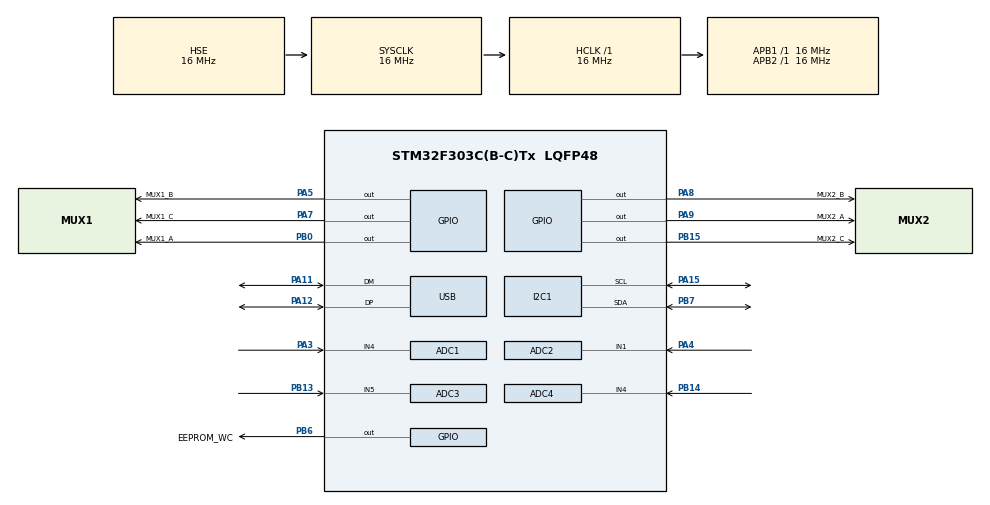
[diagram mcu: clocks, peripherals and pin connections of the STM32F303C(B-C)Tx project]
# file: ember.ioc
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ADC1.Channel-2\#ChannelRegularConversion=ADC_CHANNEL_4
ADC1.ClockPrescaler=ADC_CLOCK_SYNC_PCLK_DIV1
ADC1.Mode=ADC_DUALMODE_REGSIMULT
ADC1.NbrOfConversionFlag=1
ADC1.Offset-2\#ChannelRegularConversion=0
ADC1.OffsetNumber-2\#ChannelRegularConversion=ADC_OFFSET_NONE
ADC1.Rank-2\#ChannelRegularConversion=1
ADC1.SamplingTime-2\#ChannelRegularConversion=ADC_SAMPLETIME_7CYCLES_5
ADC1.SamplingTimeOPAMP-2\#ChannelRegularConversion=ADC_SAMPLETIME_19CYCLES_5
ADC1.TwoSamplingDelay=ADC_TWOSAMPLINGDELAY_1CYCLE
ADC1.master=1
ADC2.Channel-0\#ChannelRegularConversion=ADC_CHANNEL_1
ADC2.ClockPrescaler=ADC_CLOCK_SYNC_PCLK_DIV1
ADC2.Mode=ADC_DUALMODE_REGSIMULT
ADC2.NbrOfConversionFlag=1
ADC2.Offset-0\#ChannelRegularConversion=0
ADC2.OffsetNumber-0\#ChannelRegularConversion=ADC_OFFSET_NONE
ADC2.Rank-0\#ChannelRegularConversion=1
ADC2.SamplingTime-0\#ChannelRegularConversion=ADC_SAMPLETIME_7CYCLES_5
ADC2.SamplingTimeOPAMP-0\#ChannelRegularConversion=ADC_SAMPLETIME_4CYCLES_5
ADC3.Channel-0\#ChannelRegularConversion=ADC_CHANNEL_5
ADC3.ClockPrescaler=ADC_CLOCK_SYNC_PCLK_DIV1
ADC3.Mode=ADC_DUALMODE_REGSIMULT
ADC3.NbrOfConversionFlag=1
ADC3.Offset-0\#ChannelRegularConversion=0
ADC3.OffsetNumber-0\#ChannelRegularConversion=ADC_OFFSET_NONE
ADC3.Rank-0\#ChannelRegularConversion=1
ADC3.SamplingTime-0\#ChannelRegularConversion=ADC_SAMPLETIME_7CYCLES_5
ADC3.master=1
ADC4.Channel-1\#ChannelRegularConversion=ADC_CHANNEL_4
ADC4.ClockPrescaler=ADC_CLOCK_SYNC_PCLK_DIV1
ADC4.Mode=ADC_DUALMODE_REGSIMULT
ADC4.NbrOfConversionFlag=1
ADC4.Offset-1\#ChannelRegularConversion=0
ADC4.OffsetNumber-1\#ChannelRegularConversion=ADC_OFFSET_NONE
ADC4.Rank-1\#ChannelRegularConversion=1
ADC4.SamplingTime-1\#ChannelRegularConversion=ADC_SAMPLETIME_7CYCLES_5
ADC4.SamplingTimeOPAMP-1\#ChannelRegularConversion=ADC_SAMPLETIME_7CYCLES_5
Dma.ADC1.0.Direction=DMA_PERIPH_TO_MEMORY
Dma.ADC1.0.Instance=DMA1_Channel1
Dma.ADC1.0.MemDataAlignment=DMA_MDATAALIGN_WORD
Dma.ADC1.0.MemInc=DMA_MINC_ENABLE
Dma.ADC1.0.Mode=DMA_CIRCULAR
Dma.ADC1.0.PeriphDataAlignment=DMA_PDATAALIGN_WORD
Dma.ADC1.0.PeriphInc=DMA_PINC_DISABLE
Dma.ADC1.0.Priority=DMA_PRIORITY_LOW
Dma.ADC2.1.Direction=DMA_PERIPH_TO_MEMORY
Dma.ADC2.1.Instance=DMA2_Channel1
Dma.ADC2.1.MemDataAlignment=DMA_MDATAALIGN_WORD
Dma.ADC2.1.MemInc=DMA_MINC_ENABLE
Dma.ADC2.1.Mode=DMA_CIRCULAR
Dma.ADC2.1.PeriphDataAlignment=DMA_PDATAALIGN_WORD
Dma.ADC2.1.PeriphInc=DMA_PINC_DISABLE
Dma.ADC2.1.Priority=DMA_PRIORITY_LOW
Dma.ADC3.2.Direction=DMA_PERIPH_TO_MEMORY
Dma.ADC3.2.Instance=DMA2_Channel5
Dma.ADC3.2.MemDataAlignment=DMA_MDATAALIGN_WORD
Dma.ADC3.2.MemInc=DMA_MINC_ENABLE
Dma.ADC3.2.Mode=DMA_CIRCULAR
Dma.ADC3.2.PeriphDataAlignment=DMA_PDATAALIGN_WORD
Dma.ADC3.2.PeriphInc=DMA_PINC_DISABLE
Dma.ADC3.2.Priority=DMA_PRIORITY_LOW
Dma.ADC4.3.Direction=DMA_PERIPH_TO_MEMORY
Dma.ADC4.3.Instance=DMA2_Channel2
Dma.ADC4.3.MemDataAlignment=DMA_MDATAALIGN_WORD
Dma.ADC4.3.MemInc=DMA_MINC_ENABLE
Dma.ADC4.3.Mode=DMA_CIRCULAR
Dma.ADC4.3.PeriphDataAlignment=DMA_PDATAALIGN_WORD
Dma.ADC4.3.PeriphInc=DMA_PINC_DISABLE
Dma.ADC4.3.Priority=DMA_PRIORITY_LOW
Dma.Request0=ADC1
Dma.Request1=ADC2
Dma.Request2=ADC3
Dma.Request3=ADC4
Mcu.Family=STM32F3
Mcu.Name=STM32F303C(B-C)Tx
Mcu.Package=LQFP48
NVIC.ADC1_2_IRQn=true\:0\:0\:false\:false\:true\:true\:true\:true
NVIC.ADC3_IRQn=true\:0\:0\:false\:false\:true\:true\:true\:true
NVIC.ADC4_IRQn=true\:0\:0\:false\:false\:true\:true\:true\:true
NVIC.DMA1_Channel1_IRQn=true\:0\:0\:false\:false\:true\:false\:true\:true
NVIC.DMA2_Channel1_IRQn=true\:0\:0\:false\:false\:true\:false\:true\:true
NVIC.DMA2_Channel2_IRQn=true\:0\:0\:false\:false\:true\:false\:true\:true
NVIC.DMA2_Channel5_IRQn=true\:0\:0\:false\:false\:true\:false\:true\:true
NVIC.PriorityGroup=NVIC_PRIORITYGROUP_4
NVIC.TIM1_TRG_COM_TIM17_IRQn=true\:0\:0\:false\:false\:true\:true\:true\:true
NVIC.USB_HP_CAN_TX_IRQn=true\:0\:0\:false\:false\:true\:true\:true\:true
NVIC.USB_LP_CAN_RX0_IRQn=true\:0\:0\:false\:false\:true\:true\:true\:true
PA11.Mode=Device
PA11.Signal=USB_DM
PA12.Mode=Device
PA12.Signal=USB_DP
PA13.Mode=Serial_Wire
PA13.Signal=SYS_JTMS-SWDIO
PA14.Mode=Serial_Wire
PA14.Signal=SYS_JTCK-SWCLK
PA15.Mode=I2C
PA15.Signal=I2C1_SCL
PA3.Mode=IN4-Single-Ended
PA3.Signal=ADC1_IN4
PA4.Mode=IN1-Single-Ended
PA4.Signal=ADC2_IN1
PA5.GPIO_Label=MUX1_B
PA5.GPIO_Speed=GPIO_SPEED_FREQ_HIGH
PA5.Signal=GPIO_Output
PA7.GPIO_Label=MUX1_C
PA7.GPIO_Speed=GPIO_SPEED_FREQ_HIGH
PA7.Signal=GPIO_Output
PA8.GPIO_Label=MUX2_B
PA8.GPIO_Speed=GPIO_SPEED_FREQ_HIGH
PA8.Signal=GPIO_Output
PA9.GPIO_Label=MUX2_A
PA9.GPIO_Speed=GPIO_SPEED_FREQ_HIGH
PA9.Signal=GPIO_Output
PB0.GPIO_Label=MUX1_A
PB0.GPIO_Speed=GPIO_SPEED_FREQ_HIGH
PB0.Signal=GPIO_Output
PB13.Mode=IN5-Single-Ended
PB13.Signal=ADC3_IN5
PB14.Mode=IN4-Single-Ended
PB14.Signal=ADC4_IN4
PB15.GPIO_Label=MUX2_C
PB15.GPIO_Speed=GPIO_SPEED_FREQ_HIGH
PB15.Signal=GPIO_Output
PB6.GPIO_Label=EEPROM_WC
PB6.Signal=GPIO_Output
PB7.Mode=I2C
PB7.Signal=I2C1_SDA
PF0-OSC_IN.Mode=HSE-External-Oscillator
PF0-OSC_IN.Signal=RCC_OSC_IN
PF1-OSC_OUT.Mode=HSE-External-Oscillator
PF1-OSC_OUT.Signal=RCC_OSC_OUT
ProjectManager.HeapSize=0x200
ProjectManager.StackSize=0x400
ProjectManager.TargetToolchain=Makefile
RCC.AHBFreq_Value=16000000
RCC.APB1Freq_Value=16000000
RCC.APB1TimFreq_Value=16000000
RCC.APB2Freq_Value=16000000
RCC.APB2TimFreq_Value=16000000
RCC.CortexFreq_Value=16000000
RCC.HCLKFreq_Value=16000000
RCC.HSE_VALUE=16000000
RCC.HSI_VALUE=8000000
RCC.LSE_VALUE=32768
RCC.PLLMUL=RCC_PLL_MUL12
RCC.PLLSourceVirtualString=RCC_PLLSOURCE_HSI
RCC.SYSCLKFreq_VALUE=16000000
RCC.SYSCLKSourceVirtual=RCC_SYSCLKSOURCE_HSE
RCC.USBFreq_Value=48000000
TIM17.Period=3999
TIM17.Prescaler=15
VP_TIM17_VS_ClockSourceINT.Mode=Enable_Timer
board=custom

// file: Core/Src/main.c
/* USER CODE BEGIN Header */
/**
  ******************************************************************************
  * @file           : main.c
  * @brief          : Main program body
  ******************************************************************************
  * @attention
  *
  * Copyright (c) 2023 STMicroelectronics.
  * All rights reserved.
  *
  * This software is licensed under terms that can be found in the LICENSE file
  * in the root directory of this software component.
  * If no LICENSE file comes with this software, it is provided AS-IS.
  *
  ******************************************************************************
  */
/* USER CODE END Header */
#include "main.h"
#include "adc.h"
#include "dma.h"
#include "i2c.h"
#include "tim.h"
#include "usb.h"
#include "gpio.h"

/* USER CODE BEGIN Includes */
#include "app.h"
/* USER CODE END Includes */

void SystemClock_Config(void);

int main(void)
{
  /* USER CODE BEGIN 1 */
  usb_bootloader_init();
  /* USER CODE END 1 */

  /* MCU Configuration--------------------------------------------------------*/

  /* Reset of all peripherals, Initializes the Flash interface and the Systick. */
  HAL_Init();

  /* Configure the system clock */
  SystemClock_Config();

  /* Initialize all configured peripherals */
  MX_GPIO_Init();
  MX_DMA_Init();
  MX_ADC1_Init();
  MX_ADC2_Init();
  MX_ADC3_Init();
  MX_ADC4_Init();
  MX_USB_PCD_Init();
  MX_TIM17_Init();
  MX_I2C1_Init();
  /* USER CODE BEGIN 2 */
  setup();
  /* USER CODE END 2 */

  /* Infinite loop */
  /* USER CODE BEGIN WHILE */
  while (1)
  {
    loop();
    /* USER CODE END WHILE */

  }
}

void SystemClock_Config(void)
{
  RCC_OscInitTypeDef RCC_OscInitStruct = {0};
  RCC_ClkInitTypeDef RCC_ClkInitStruct = {0};
  RCC_PeriphCLKInitTypeDef PeriphClkInit = {0};

  /** Initializes the RCC Oscillators according to the specified parameters
  * in the RCC_OscInitTypeDef structure.
  */
  RCC_OscInitStruct.OscillatorType = RCC_OSCILLATORTYPE_HSI|RCC_OSCILLATORTYPE_HSE;
  RCC_OscInitStruct.HSEState = RCC_HSE_ON;
  RCC_OscInitStruct.HSEPredivValue = RCC_HSE_PREDIV_DIV1;
  RCC_OscInitStruct.HSIState = RCC_HSI_ON;
  RCC_OscInitStruct.HSICalibrationValue = RCC_HSICALIBRATION_DEFAULT;
  RCC_OscInitStruct.PLL.PLLState = RCC_PLL_ON;
  RCC_OscInitStruct.PLL.PLLSource = RCC_PLLSOURCE_HSE;
  RCC_OscInitStruct.PLL.PLLMUL = RCC_PLL_MUL3;
  if (HAL_RCC_OscConfig(&RCC_OscInitStruct) != HAL_OK)
  {
    Error_Handler();
  }

  /** Initializes the CPU, AHB and APB buses clocks
  */
  RCC_ClkInitStruct.ClockType = RCC_CLOCKTYPE_HCLK|RCC_CLOCKTYPE_SYSCLK
                              |RCC_CLOCKTYPE_PCLK1|RCC_CLOCKTYPE_PCLK2;
  RCC_ClkInitStruct.SYSCLKSource = RCC_SYSCLKSOURCE_HSE;
  RCC_ClkInitStruct.AHBCLKDivider = RCC_SYSCLK_DIV1;
  RCC_ClkInitStruct.APB1CLKDivider = RCC_HCLK_DIV1;
  RCC_ClkInitStruct.APB2CLKDivider = RCC_HCLK_DIV1;

  if (HAL_RCC_ClockConfig(&RCC_ClkInitStruct, FLASH_LATENCY_0) != HAL_OK)
  {
    Error_Handler();
  }
  PeriphClkInit.PeriphClockSelection = RCC_PERIPHCLK_USB|RCC_PERIPHCLK_I2C1;
  PeriphClkInit.I2c1ClockSelection = RCC_I2C1CLKSOURCE_HSI;
  PeriphClkInit.USBClockSelection = RCC_USBCLKSOURCE_PLL;
  if (HAL_RCCEx_PeriphCLKConfig(&PeriphClkInit) != HAL_OK)
  {
    Error_Handler();
  }
}

void Error_Handler(void)
{
  __disable_irq();
  while (1)
  {
  }
}
